# BL702 register map
Vendor: Bouffalo Lab; Series: WiFi BT; File version: 1.0
Registers are 32-bit, read-write, reset 0x0 unless marked. A register's access mark holds for its fields unless they carry their own. Offsets are from the block's base; [hi:lo] are bit positions.

## PDS — Sleep control (Power Down Sleep)
Base 0x4000E000
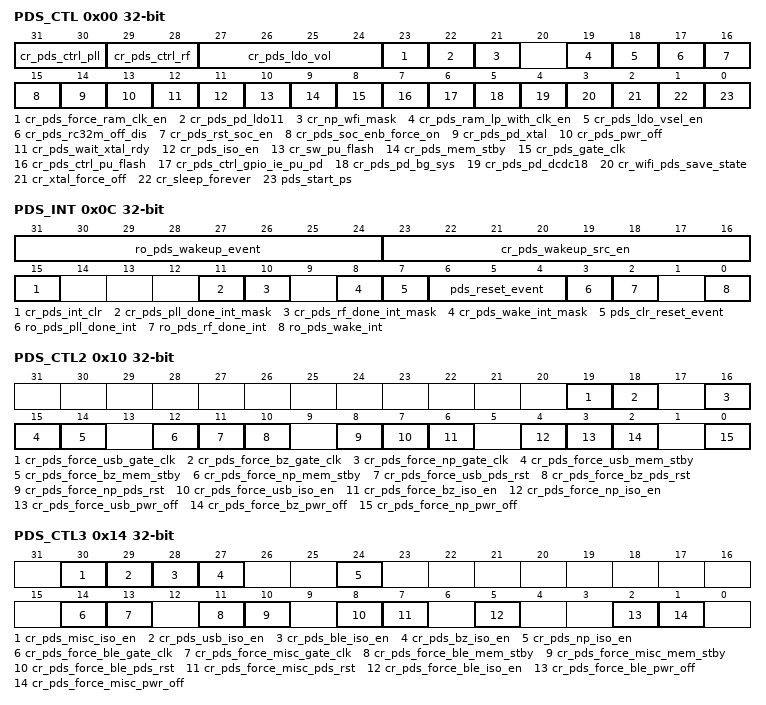
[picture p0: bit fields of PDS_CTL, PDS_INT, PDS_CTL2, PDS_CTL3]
0x00 PDS_CTL
  [31:30] cr_pds_ctrl_pll, [29:28] cr_pds_ctrl_rf, [27:24] cr_pds_ldo_vol, [23] cr_pds_force_ram_clk_en, [22] cr_pds_pd_ldo11, [21] cr_np_wfi_mask, [19] cr_pds_ram_lp_with_clk_en, [18] cr_pds_ldo_vsel_en, [17] cr_pds_rc32m_off_dis, [16] cr_pds_rst_soc_en, [15] cr_pds_soc_enb_force_on, [14] cr_pds_pd_xtal, [13] cr_pds_pwr_off, [12] cr_pds_wait_xtal_rdy, [11] cr_pds_iso_en, [10] cr_sw_pu_flash, [9] cr_pds_mem_stby, [8] cr_pds_gate_clk, [7] cr_pds_ctrl_pu_flash, [6] cr_pds_ctrl_gpio_ie_pu_pd, [5] cr_pds_pd_bg_sys, [4] cr_pds_pd_dcdc18, [3] cr_wifi_pds_save_state, [2] cr_xtal_force_off, [1] cr_sleep_forever, [0] pds_start_ps
0x04 PDS_TIME1
  [31:0] cr_sleep_duration
0x0C PDS_INT
  [31:24] ro_pds_wakeup_event, [23:16] cr_pds_wakeup_src_en, [15] cr_pds_int_clr, [11] cr_pds_pll_done_int_mask, [10] cr_pds_rf_done_int_mask, [8] cr_pds_wake_int_mask, [7] pds_clr_reset_event, [6:4] pds_reset_event, [3] ro_pds_pll_done_int, [2] ro_pds_rf_done_int, [0] ro_pds_wake_int
0x10 PDS_CTL2
  [19] cr_pds_force_usb_gate_clk, [18] cr_pds_force_bz_gate_clk, [16] cr_pds_force_np_gate_clk, [15] cr_pds_force_usb_mem_stby, [14] cr_pds_force_bz_mem_stby, [12] cr_pds_force_np_mem_stby, [11] cr_pds_force_usb_pds_rst, [10] cr_pds_force_bz_pds_rst, [8] cr_pds_force_np_pds_rst, [7] cr_pds_force_usb_iso_en, [6] cr_pds_force_bz_iso_en, [4] cr_pds_force_np_iso_en, [3] cr_pds_force_usb_pwr_off, [2] cr_pds_force_bz_pwr_off, [0] cr_pds_force_np_pwr_off
0x14 PDS_CTL3
  [30] cr_pds_misc_iso_en, [29] cr_pds_usb_iso_en, [28] cr_pds_ble_iso_en, [27] cr_pds_bz_iso_en, [24] cr_pds_np_iso_en, [14] cr_pds_force_ble_gate_clk, [13] cr_pds_force_misc_gate_clk, [11] cr_pds_force_ble_mem_stby, [10] cr_pds_force_misc_mem_stby, [8] cr_pds_force_ble_pds_rst, [7] cr_pds_force_misc_pds_rst, [5] cr_pds_force_ble_iso_en, [2] cr_pds_force_ble_pwr_off, [1] cr_pds_force_misc_pwr_off
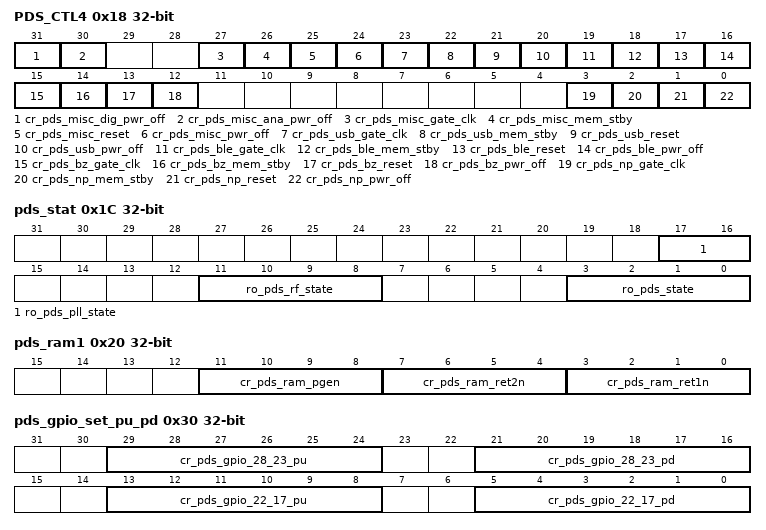
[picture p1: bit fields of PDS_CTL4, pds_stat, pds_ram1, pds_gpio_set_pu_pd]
0x18 PDS_CTL4
  [31] cr_pds_misc_dig_pwr_off, [30] cr_pds_misc_ana_pwr_off, [27] cr_pds_misc_gate_clk, [26] cr_pds_misc_mem_stby, [25] cr_pds_misc_reset, [24] cr_pds_misc_pwr_off, [23] cr_pds_usb_gate_clk, [22] cr_pds_usb_mem_stby, [21] cr_pds_usb_reset, [20] cr_pds_usb_pwr_off, [19] cr_pds_ble_gate_clk, [18] cr_pds_ble_mem_stby, [17] cr_pds_ble_reset, [16] cr_pds_ble_pwr_off, [15] cr_pds_bz_gate_clk, [14] cr_pds_bz_mem_stby, [13] cr_pds_bz_reset, [12] cr_pds_bz_pwr_off, [3] cr_pds_np_gate_clk, [2] cr_pds_np_mem_stby, [1] cr_pds_np_reset, [0] cr_pds_np_pwr_off
0x1C pds_stat
  [17:16] ro_pds_pll_state, [11:8] ro_pds_rf_state, [3:0] ro_pds_state
0x20 pds_ram1
  [11:8] cr_pds_ram_pgen, [7:4] cr_pds_ram_ret2n, [3:0] cr_pds_ram_ret1n
0x30 pds_gpio_set_pu_pd
  [29:24] cr_pds_gpio_28_23_pu, [21:16] cr_pds_gpio_28_23_pd, [13:8] cr_pds_gpio_22_17_pu, [5:0] cr_pds_gpio_22_17_pd
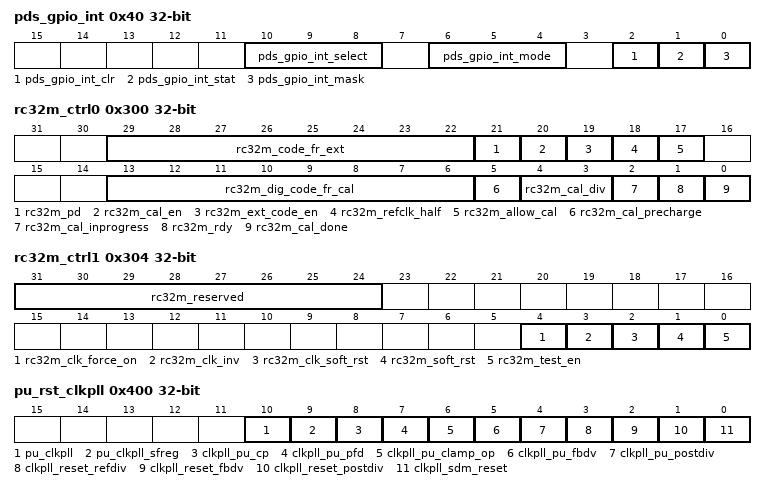
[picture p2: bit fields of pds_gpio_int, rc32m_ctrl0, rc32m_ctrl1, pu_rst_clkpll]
0x40 pds_gpio_int
  [10:8] pds_gpio_int_select, [6:4] pds_gpio_int_mode, [2] pds_gpio_int_clr, [1] pds_gpio_int_stat, [0] pds_gpio_int_mask
0x300 rc32m_ctrl0
  [29:22] rc32m_code_fr_ext, [21] rc32m_pd, [20] rc32m_cal_en, [19] rc32m_ext_code_en, [18] rc32m_refclk_half, [17] rc32m_allow_cal, [13:6] rc32m_dig_code_fr_cal, [5] rc32m_cal_precharge, [4:3] rc32m_cal_div, [2] rc32m_cal_inprogress, [1] rc32m_rdy, [0] rc32m_cal_done
0x304 rc32m_ctrl1
  [31:24] rc32m_reserved, [4] rc32m_clk_force_on, [3] rc32m_clk_inv, [2] rc32m_clk_soft_rst, [1] rc32m_soft_rst, [0] rc32m_test_en
0x400 pu_rst_clkpll
  [10] pu_clkpll, [9] pu_clkpll_sfreg, [8] clkpll_pu_cp, [7] clkpll_pu_pfd, [6] clkpll_pu_clamp_op, [5] clkpll_pu_fbdv, [4] clkpll_pu_postdiv, [3] clkpll_reset_refdiv, [2] clkpll_reset_fbdv, [1] clkpll_reset_postdiv, [0] clkpll_sdm_reset
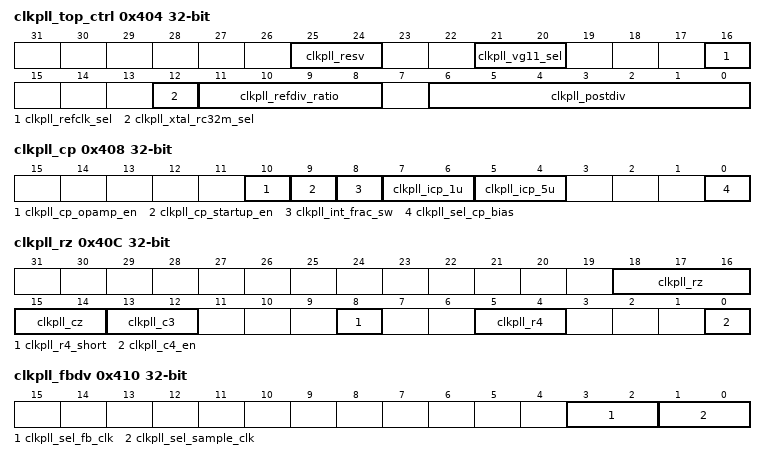
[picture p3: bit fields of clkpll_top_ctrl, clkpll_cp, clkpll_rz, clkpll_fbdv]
0x404 clkpll_top_ctrl
  [25:24] clkpll_resv, [21:20] clkpll_vg11_sel, [16] clkpll_refclk_sel, [12] clkpll_xtal_rc32m_sel, [11:8] clkpll_refdiv_ratio, [6:0] clkpll_postdiv
0x408 clkpll_cp
  [10] clkpll_cp_opamp_en, [9] clkpll_cp_startup_en, [8] clkpll_int_frac_sw, [7:6] clkpll_icp_1u, [5:4] clkpll_icp_5u, [0] clkpll_sel_cp_bias
0x40C clkpll_rz
  [18:16] clkpll_rz, [15:14] clkpll_cz, [13:12] clkpll_c3, [8] clkpll_r4_short, [5:4] clkpll_r4, [0] clkpll_c4_en
0x410 clkpll_fbdv
  [3:2] clkpll_sel_fb_clk, [1:0] clkpll_sel_sample_clk
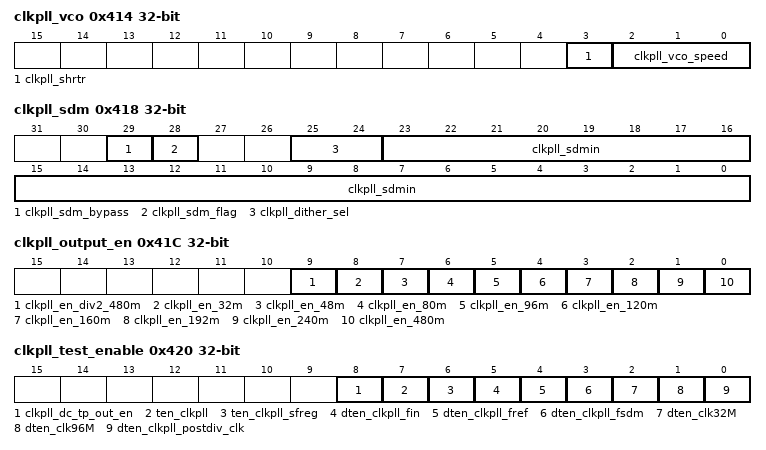
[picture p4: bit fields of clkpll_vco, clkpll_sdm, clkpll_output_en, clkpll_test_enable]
0x414 clkpll_vco
  [3] clkpll_shrtr, [2:0] clkpll_vco_speed
0x418 clkpll_sdm
  [29] clkpll_sdm_bypass, [28] clkpll_sdm_flag, [25:24] clkpll_dither_sel, [23:0] clkpll_sdmin
0x41C clkpll_output_en
  [9] clkpll_en_div2_480m, [8] clkpll_en_32m, [7] clkpll_en_48m, [6] clkpll_en_80m, [5] clkpll_en_96m, [4] clkpll_en_120m, [3] clkpll_en_160m, [2] clkpll_en_192m, [1] clkpll_en_240m, [0] clkpll_en_480m
0x420 clkpll_test_enable
  [8] clkpll_dc_tp_out_en, [7] ten_clkpll, [6] ten_clkpll_sfreg, [5] dten_clkpll_fin, [4] dten_clkpll_fref, [3] dten_clkpll_fsdm, [2] dten_clk32M, [1] dten_clk96M, [0] dten_clkpll_postdiv_clk
